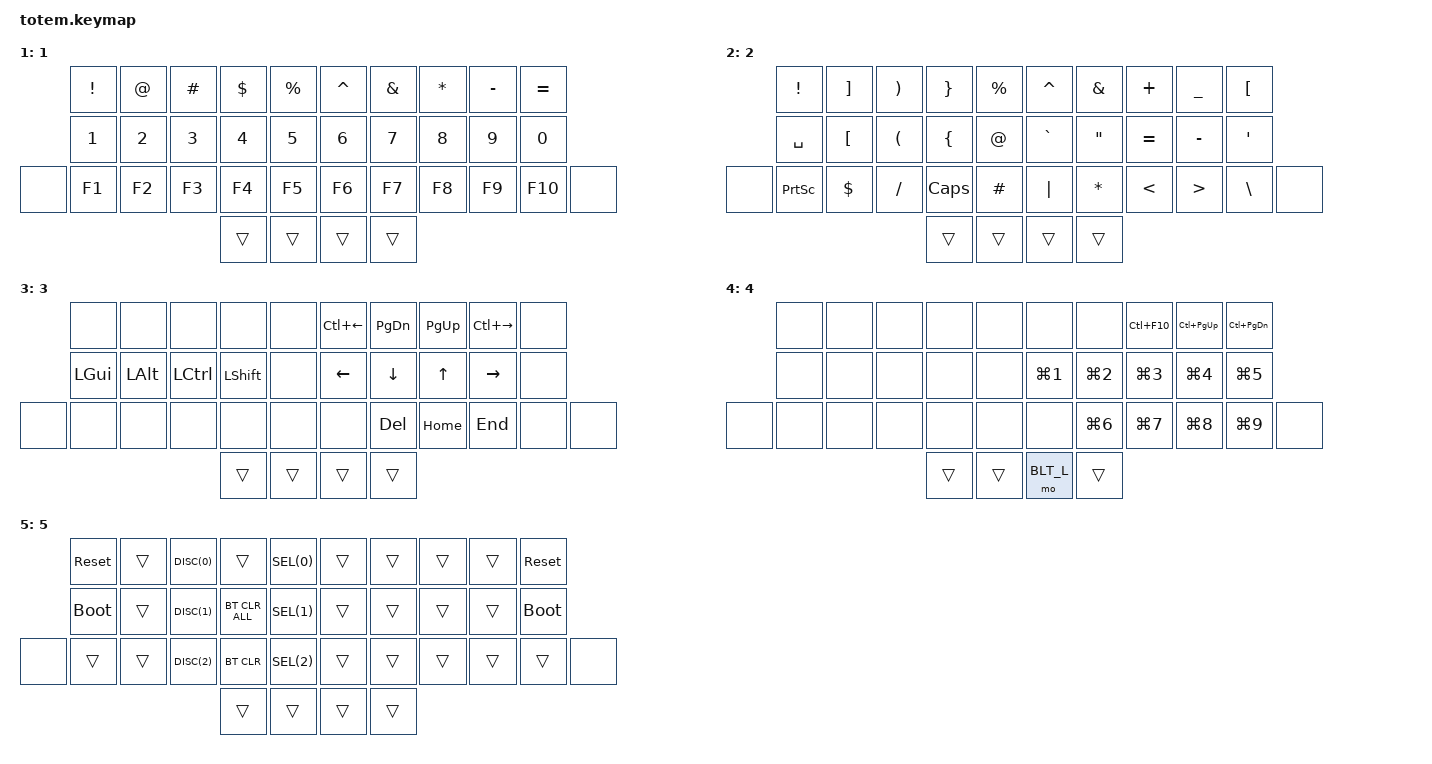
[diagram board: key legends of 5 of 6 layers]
// Copyright (c) 2022 The ZMK Contributors
// SPDX-License-Identifier: MIT
// Migrated from Ferris (Cradio) configuration
//
//                                                        ▀▀▀▀▀     ▀▀▀▀▀          ▀▀█▀▀
//                                                        ▄▀▀▀▄  ▄  ▄▀▀▀▄  ▄  ▄▀▀▀▄  █  ▄▀▀▀▄
//                                                        █   █  █  █   █  █  █   █  █  █   █
//                                                         ▀▀▀   █   ▀▀▀   █   ▀▀▀   ▀   ▀▀▀
//                                                               █      ▄▄▄█▄▄▄    █   █  
//                                                               ▀      █  █  █     █▄█
//                                                             ▀▀▀▀▀    █  █  █      ▀
//                                                                      ▀  ▀  ▀
//
// ▄▄▄▄▄▄▄▄▄▄▄▄▄▄▄▄▄▄▄▄▄▄▄▄▄▄▄▄▄▄▄▄▄▄▄▄▄▄▄▄▄▄▄▄▄▄▄▄▄▄▄▄▄▄▄▄▄▄▄▄▄▄▄▄▄▄▄▄▄▄▄▄▄▄▄▄▄▄▄▄▄▄▄▄▄▄▄▄▄▄▄▄▄▄▄▄▄▄▄▄▄▄▄▄▄▄▄▄▄▄▄▄▄▄▄▄▄▄▄▄▄▄▄▄▄▄▄▄▄▄▄▄▄▄▄▄▄▄▄▄▄▄▄▄▄▄▄▄▄
#include <behaviors.dtsi>
#include <dt-bindings/zmk/keys.h>
#include <dt-bindings/zmk/bt.h>

#include "zmk-helpers/helper.h"

/* Left-hand HRMs. */
ZMK_HOLD_TAP(hml,
    flavor = "balanced";
    tapping-term-ms = <280>;
    quick-tap-ms = <175>;
    require-prior-idle-ms = <150>;
    bindings = <&kp>, <&kp>;
    hold-trigger-key-positions = <5 6 7 8 9 15 16 17 18 19 26 27 28 29 30 31 32 33 34 35>;
    hold-trigger-on-release;
)

/* Right-hand HRMs. */
ZMK_HOLD_TAP(hmr,
    flavor = "balanced";
    tapping-term-ms = <280>;
    quick-tap-ms = <175>;
    require-prior-idle-ms = <150>;
    bindings = <&kp>, <&kp>;
    hold-trigger-key-positions = <0 1 2 3 4 10 11 12 13 14 20 21 22 23 24 25 32 33 34 35>;
    hold-trigger-on-release;
)

// Layers
#define DEFAULT_L 0
#define NUM_L  1
#define SYM_L  2
#define ARR_L  3
#define WIN_L  4
#define BLT_L  5

// Layer switchers
#define SYMSPACE  &lt SYM_L SPACE
#define NUMTAB &lt NUM_L TAB
#define ARRET &lt ARR_L RET
#define WINBSP &lt WIN_L BSPC

// Home row mods macro
#define HRML(k1,k2,k3,k4) &hml LGUI k1  &hml LALT k2  &hml LCTRL k3  &hml LSHFT k4
#define HRMR(k1,k2,k3,k4) &hmr RSHFT k1  &hmr RCTRL k2  &hmr LALT k3  &hmr RGUI k4
#define HRMA(k1) &hm RALT k1

// BT macro
#define DISC(profile) &bt BT_DISC profile
#define SEL(profile) &bt BT_SEL profile
#define CLR &bt BT_CLR
#define CLR_ALL &bt BT_CLR_ALL

// OS tricks
#define WLIST &kp LC(F10) // window list
#define CPGUP &kp LC(PG_UP) // Control + Page Up
#define CPGDN &kp LC(PG_DN) // Control + Page Down
#define CLFT &kp LC(LEFT) // Control + Left
#define CRGHT &kp LC(RIGHT) // Control + Right

// Adjust layer switching keys behavior
&lt {
    flavor = "balanced";
    tapping-term-ms = <200>;
    quick-tap-ms = <200>;
};

/ {
    behaviors {
        hm: homerow_mods {
            compatible = "zmk,behavior-hold-tap";
            #binding-cells = <2>;
            flavor = "balanced";
            hold-trigger-on-release;
            // require-prior-idle-ms = <150>;
            tapping-term-ms = <1000>;
            // quick-tap-ms = <175>;
            bindings = <&kp>, <&kp>;
        };
    };

    combos {
        compatible = "zmk,combos";

        we {
            bindings = <&kp ESCAPE>;
            key-positions = <1 2>;
            require-prior-idle-ms = <200>;
        };

        io {
            bindings = <&kp CLCK>;
            key-positions = <7 8>;
            require-prior-idle-ms = <200>;
        };

        ei {
            bindings = <&caps_word>;
            key-positions = <2 7>;
        };

        hy {
            bindings = <&kp LC(BACKSPACE)>;
            key-positions = <5 15>;
        };

        hn {
            bindings = <&kp LA(BACKSPACE)>;
            key-positions = <15 25>;
        };

        tg {
            bindings = <&kp SQT>;
            key-positions = <4 14>;
        };

        gb {
            bindings = <&kp DQT>;
            key-positions = <14 24>;
        };
    };

    keymap {
        compatible = "zmk,keymap";
        
        default_layer {
            label = "0";
            bindings = <
        //╭──────────┬──────────┬──────────┬──────────┬──────────╮   ╭──────────┬──────────┬──────────┬──────────┬──────────╮
        //│  Q       │  W       │  E       │  R       │  T       │   │  Y       │  U       │  I       │  O       │  P       │
            &kp Q      &kp W      &kp E      &kp R      &kp T          &kp Y      &kp U      &kp I      &kp O      &kp P
        //├──────────┼──────────┼──────────┼──────────┼──────────┤   ├──────────┼──────────┼──────────┼──────────┼──────────┤
        //│  A       │  S       │  D       │  F       │  G       │   │  H       │  J       │  K       │  L       │  ;       │
      &hm LGUI A     &hm LALT S   &hm LCTRL D   &hm LSHFT F &kp G      &kp H      HRMR(J,        K,         L,        SEMI)
        //├──────────┼──────────┼──────────┼──────────┼──────────┤   ├──────────┼──────────┼──────────┼──────────┼──────────┤
        //│  Z       │  X       │  C       │  V       │  B       │   │  N       │  M       │ , <      │ . >      │ / ?      │
   &none   &kp Z      HRMA(X)    &kp C      &kp V      &kp B          &kp N      &kp M      &kp COMMA  HRMA(DOT)  &kp FSLH   &none
        //╰──────────┴──────────┴──────────┼──────────┼──────────┤   ├──────────┼──────────┼──────────┴──────────┴──────────╯
                                             SYMSPACE   NUMTAB         ARRET      WINBSP
        //                                 ╰──────────┴──────────╯   ╰──────────┴──────────╯
            >;
        };

        num_layer {
            label = "1";
            bindings = <
        //╭──────────┬──────────┬──────────┬──────────┬──────────╮   ╭──────────┬──────────┬──────────┬──────────┬──────────╮
        //│ !        │  @       │  #       │  $       │  %       │   │ ^        │ &        │ *        │ -        │  =       │
           &kp EXCL    &kp AT     &kp HASH   &kp DLLR   &kp PRCNT     &kp CARET  &kp AMPS   &kp ASTRK  &kp MINUS   &kp EQUAL
        //├──────────┼──────────┼──────────┼──────────┼──────────┤   ├──────────┼──────────┼──────────┼──────────┼──────────┤
        //│ 1        │  2       │  3       │  4       │  5       │   │ 6        │ 7        │ 8        │ 9        │  0       │
            &kp N1     &kp N2     &kp N3     &kp N4     &kp N5         &kp N6     &kp N7     &kp N8     &kp N9     &kp N0
        //├──────────┼──────────┼──────────┼──────────┼──────────┤   ├──────────┼──────────┼──────────┼──────────┼──────────┤
        //│  F1      │  F2      │  F3      │  F4      │  F5      │   │  F6      │  F7      │  F8      │  F9      │  F10     │
   &none    &kp F1     &kp F2     &kp F3     &kp F4     &kp F5         &kp F6     &kp F7     &kp F8     &kp F9     &kp F10    &none
        //╰──────────┴──────────┴──────────┼──────────┼──────────┤   ├──────────┼──────────┼──────────┴──────────┴──────────╯
                                             &trans     &trans         &trans     &trans
        //                                 ╰──────────┴──────────╯   ╰──────────┴──────────╯
            >;
        };

        sym_layer {
            label = "2";
            bindings = <
        //╭──────────┬──────────┬──────────┬──────────┬──────────╮   ╭──────────┬──────────┬──────────┬──────────┬──────────╮
        //│  !       │  ]       │  )       │  }       │  %       │   │  ^       │  &       │  +       │  _       │  [       │
            &kp EXCL   &kp RBKT   &kp RPAR   &kp RBRC   &kp PRCNT      &kp CARET  &kp AMPS   &kp PLUS   &kp UNDER  &kp LBKT
        //├──────────┼──────────┼──────────┼──────────┼──────────┤   ├──────────┼──────────┼──────────┼──────────┼──────────┤
        //│          │  [       │  (       │  {       │  @       │   │  `       │  "       │  =       │  -       │  '       │
            &kp SPACE  &kp LBKT   &kp LPAR   &kp LBRC   &kp AT         &kp GRAVE  &kp DQT   &kp EQUAL  &kp MINUS   &kp SQT
        //├──────────┼──────────┼──────────┼──────────┼──────────┤   ├──────────┼──────────┼──────────┼──────────┼──────────┤
        //│  PSCRN   │  $       │  /       │  CAPS    │  #       │   │  │       │   *      │  <       │  >       │  \       │
   &none    &kp PSCRN  &kp DLLR   &kp FSLH   &kp CLCK   &kp HASH       &kp PIPE   &kp STAR   &kp LT     &kp GT     &kp BSLH   &none
        //╰──────────┴──────────┴──────────┼──────────┼──────────┤   ├──────────┼──────────┼──────────┴──────────┴──────────╯
                                             &trans     &trans         &trans     &trans
        //                                 ╰──────────┴──────────╯   ╰──────────┴──────────╯
            >;
        };

        arrow_layer {
            label = "3";
            bindings = <
        //╭──────────┬──────────┬──────────┬──────────┬──────────╮   ╭──────────┬──────────┬──────────┬──────────┬──────────╮
        //│          │          │          │          │          │   │ CLFT     │  PG_DN   │  PG_UP   │  CRGHT   │          │
            &none      &none      &none      &none      &none          CLFT       &kp PG_DN  &kp PG_UP   CRGHT     &none
        //├──────────┼──────────┼──────────┼──────────┼──────────┤   ├──────────┼──────────┼──────────┼──────────┼──────────┤
        //│  GUI     │  ALT     │  CTRL    │  SHIFT   │          │   │  <-      │  DOWN    │  UP      │  ->      │          │
            &kp LGUI   &kp LALT   &kp LCTRL  &kp LSHIFT &none          &kp LEFT   &kp DOWN   &kp UP     &kp RIGHT  &none
        //├──────────┼──────────┼──────────┼──────────┼──────────┤   ├──────────┼──────────┼──────────┼──────────┼──────────┤
        //│          │          │          │          │          │   │          │  DEL     │  HOME    │  END     │          │
   &none    &none      &none      &none      &none      &none          &none      &kp DEL    &kp HOME   &kp END    &none      &none
        //╰──────────┴──────────┴──────────┼──────────┼──────────┤   ├──────────┼──────────┼──────────┴──────────┴──────────╯
                                             &trans     &trans         &trans     &trans
        //                                 ╰──────────┴──────────╯   ╰──────────┴──────────╯
            >;
        };

        window_layer {
            label = "4";
            bindings = <
        //╭──────────┬──────────┬──────────┬──────────┬──────────╮   ╭──────────┬──────────┬──────────┬──────────┬──────────╮
        //│          │          │          │          │          │   │          │          │  WLIST   │  PG_UP   │  PG_DN   │
            &none      &none      &none      &none      &none          &none      &none       WLIST      CPGUP      CPGDN
        //├──────────┼──────────┼──────────┼──────────┼──────────┤   ├──────────┼──────────┼──────────┼──────────┼──────────┤
        //│          │          │          │          │          │   │  WIN+1   │  WIN+2   │  WIN+3   │  WIN+4   │  WIN+5   │
            &none      &none      &none      &none      &none         &kp LG(N1) &kp LG(N2) &kp LG(N3) &kp LG(N4) &kp LG(N5)
        //├──────────┼──────────┼──────────┼──────────┼──────────┤   ├──────────┼──────────┼──────────┼──────────┼──────────┤
        //│          │          │          │          │          │   │  WIN+6   │  WIN+7   │  WIN+8   │  WIN+9   │          │
   &none    &none      &none      &none      &none      &none          &none     &kp LG(N6) &kp LG(N7) &kp LG(N8) &kp LG(N9)  &none
        //╰──────────┴──────────┴──────────┼──────────┼──────────┤   ├──────────┼──────────┼──────────┴──────────┴──────────╯
                                             &trans     &trans         &mo BLT_L  &trans
        //                                 ╰──────────┴──────────╯   ╰──────────┴──────────╯
            >;
        };

        bt_layer {
            label = "5";
            bindings = <
        //╭──────────┬──────────┬──────────┬──────────┬──────────╮   ╭──────────┬──────────┬──────────┬──────────┬──────────╮
        //│ RESET    │          │  DISC 0  │          │PROFILE 0 │   │          │          │          │          │  RESET   │
           &sys_reset  &trans     DISC(0)     &trans    SEL(0)         &trans     &trans     &trans     &trans    &sys_reset
        //├──────────┼──────────┼──────────┼──────────┼──────────┤   ├──────────┼──────────┼──────────┼──────────┼──────────┤
        //│BOOTLOADER│          │  DISC 1  │ CLEAR ALL│PROFILE 1 │   │          │          │          │          │BOOTLOADER│
          &bootloader  &trans     DISC(1)     CLR_ALL   SEL(1)         &trans     &trans     &trans     &trans    &bootloader
        //├──────────┼──────────┼──────────┼──────────┼──────────┤   ├──────────┼──────────┼──────────┼──────────┼──────────┤
        //│          │          │  DISC 2  │ CLEAR BT │PROFILE 2 │   │          │          │          │          │          │
   &none    &trans     &trans     DISC(2)     CLR       SEL(2)         &trans     &trans     &trans     &trans     &trans     &none
        //╰──────────┴──────────┴──────────┼──────────┼──────────┤   ├──────────┼──────────┼──────────┴──────────┴──────────╯
                                             &trans     &trans         &trans     &trans
        //                                 ╰──────────┴──────────╯   ╰──────────┴──────────╯
            >;
        };
    };

    conditional_layers {
        compatible = "zmk,conditional-layers";
        tri_layer {
            if-layers = <1 2>;
            then-layer = <3>;
        };
    };
};
